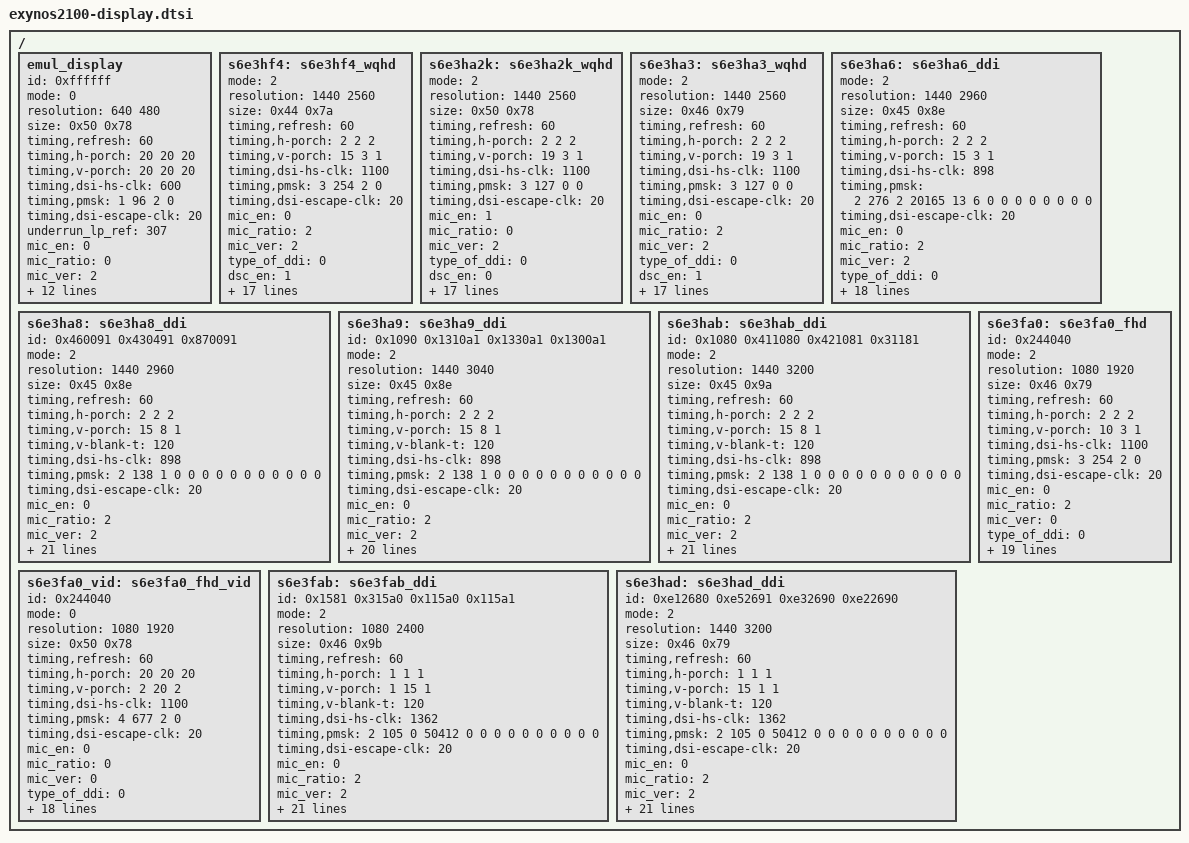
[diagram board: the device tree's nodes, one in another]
// SPDX-License-Identifier: GPL-2.0-only
/*
 * Exynos2100 LCD Panel Device Tree Source
 *
 * Copyright (C) 2026 Samsung Electronics Co., Ltd.
 *		http://www.samsung.com
 *
 */

/ {
	fragment@lcd {
		target-path = "/";
		__overlay__ {
			emul_display: emul_display {
				id = <0xffffff>;
				mode = <0>;
				resolution = <640 480>;
				size = <0x50 0x78>;
				timing,refresh = <60>;
				timing,h-porch = <20 20 20>;
				timing,v-porch = <20 20 20>;
				timing,dsi-hs-clk = <600>;
				timing,pmsk = <1 96 2 0>;
				timing,dsi-escape-clk = <20>;
				underrun_lp_ref = <307>;
				mic_en = <0>;
				mic_ratio = <0>;
				mic_ver = <2>;
				type_of_ddi = <0>;
				dsc_en = <0>;
				dsc_cnt = <0>;
				dsc_slice_num = <0>;
				data_lane = <4>;
				cmd_underrun_lp_ref = <1203>;
				vt_compensation = <10731>;
				hdr_num = <0>;
				hdr_type = <0 0 0 0>;
				hdr_max_luma = <0>;
				hdr_max_avg_luma = <0>;
				hdr_min_luma = <0>;
			};

			s6e3hf4: s6e3hf4_wqhd {
				mode = <2>;
				resolution = <1440 2560>;
				size = <0x44 0x7a>;
				timing,refresh = <60>;
				timing,h-porch = <2 2 2>;
				timing,v-porch = <15 3 1>;
				timing,dsi-hs-clk = <1100>;
				timing,pmsk = <3 254 2 0>;
				timing,dsi-escape-clk = <20>;
				mic_en = <0>;
				mic_ratio = <2>;
				mic_ver = <2>;
				type_of_ddi = <0>;
				dsc_en = <1>;
				dsc_cnt = <2>;
				dsc_slice_num = <4>;
				dsc_slice_h = <64>;
				data_lane = <4>;
				cmd_underrun_lp_ref = <5629>;
				mres_en = <0>;
				mres_number = <1>;
				mres_width = <1440 0 0>;
				mres_height = <2560 0 0>;
				mres_dsc_width = <360 0 0>;
				mres_dsc_height = <64 0 0>;
				mres_dsc_en = <1 0 0>;
				hdr_num = <1>;
				hdr_type = <2 0 0 0>;
				hdr_max_luma = <5400000>;
				hdr_max_avg_luma = <1200000>;
				hdr_min_luma = <5>;
			};

			s6e3ha2k: s6e3ha2k_wqhd {
				mode = <2>;
				resolution = <1440 2560>;
				size = <0x50 0x78>;
				timing,refresh = <60>;
				timing,h-porch = <2 2 2>;
				timing,v-porch = <19 3 1>;
				timing,dsi-hs-clk = <1100>;
				timing,pmsk = <3 127 0 0>;
				timing,dsi-escape-clk = <20>;
				mic_en = <1>;
				mic_ratio = <0>;
				mic_ver = <2>;
				type_of_ddi = <0>;
				dsc_en = <0>;
				dsc_cnt = <0>;
				dsc_slice_num = <0>;
				dsc_slice_h = <0>;
				data_lane = <4>;
				cmd_underrun_lp_ref = <1203>;
				mres_en = <0>;
				mres_number = <1>;
				mres_width = <1440 0 0>;
				mres_height = <2560 0 0>;
				mres_dsc_width = <0 0 0>;
				mres_dsc_height = <0 0 0>;
				mres_dsc_en = <0 0 0>;
				hdr_num = <1>;
				hdr_type = <2 0 0 0>;
				hdr_max_luma = <5400000>;
				hdr_max_avg_luma = <1200000>;
				hdr_min_luma = <5>;
			};

			s6e3ha3: s6e3ha3_wqhd {
				mode = <2>;
				resolution = <1440 2560>;
				size = <0x46 0x79>;
				timing,refresh = <60>;
				timing,h-porch = <2 2 2>;
				timing,v-porch = <19 3 1>;
				timing,dsi-hs-clk = <1100>;
				timing,pmsk = <3 127 0 0>;
				timing,dsi-escape-clk = <20>;
				mic_en = <0>;
				mic_ratio = <2>;
				mic_ver = <2>;
				type_of_ddi = <0>;
				dsc_en = <1>;
				dsc_cnt = <1>;
				dsc_slice_num = <1>;
				dsc_slice_h = <32>;
				data_lane = <4>;
				cmd_underrun_lp_ref = <1203>;
				mres_en = <0>;
				mres_number = <1>;
				mres_width = <1440 0 0>;
				mres_height = <2560 0 0>;
				mres_dsc_width = <1440 0 0>;
				mres_dsc_height = <32 0 0>;
				mres_dsc_en = <1 0 0>;
				hdr_num = <1>;
				hdr_type = <2 0 0 0>;
				hdr_max_luma = <5400000>;
				hdr_max_avg_luma = <1200000>;
				hdr_min_luma = <5>;
			};

			s6e3ha6: s6e3ha6_ddi {
				mode = <2>;
				resolution = <1440 2960>;
				size = <0x45 0x8e>;
				timing,refresh = <60>;
				timing,h-porch = <2 2 2>;
				timing,v-porch = <15 3 1>;
				timing,dsi-hs-clk = <898>;
				timing,pmsk = <2 276 2 20165 13 6 0 0 0 0 0 0 0 0>;
				timing,dsi-escape-clk = <20>;
				mic_en = <0>;
				mic_ratio = <2>;
				mic_ver = <2>;
				type_of_ddi = <0>;
				dsc_en = <1>;
				dsc_cnt = <2>;
				dsc_slice_num = <2>;
				dsc_slice_h = <40>;
				data_lane = <4>;
				cmd_underrun_lp_ref = <3744 5359 4367>;
				mres_en = <1>;
				mres_number = <3>;
				mres_width = <1440 1080 720>;
				mres_height = <2960 2220 1480>;
				mres_dsc_width = <720 540 360>;
				mres_dsc_height = <40 30 74>;
				mres_dsc_en = <1 1 0>;
				hdr_num = <1>;
				hdr_type = <2 0 0 0>;
				hdr_max_luma = <5400000>;
				hdr_max_avg_luma = <1200000>;
				hdr_min_luma = <5>;
			};

			s6e3ha8: s6e3ha8_ddi {
				id = <0x460091 0x430491 0x870091>;
				mode = <2>;
				resolution = <1440 2960>;
				size = <0x45 0x8e>;
				timing,refresh = <60>;
				timing,h-porch = <2 2 2>;
				timing,v-porch = <15 8 1>;
				timing,v-blank-t = <120>;
				timing,dsi-hs-clk = <898>;
				timing,pmsk = <2 138 1 0 0 0 0 0 0 0 0 0 0 0>;
				timing,dsi-escape-clk = <20>;
				mic_en = <0>;
				mic_ratio = <2>;
				mic_ver = <2>;
				type_of_ddi = <0>;
				dsc_en = <1>;
				dsc_cnt = <2>;
				dsc_slice_num = <2>;
				dsc_slice_h = <40>;
				data_lane = <4>;
				mres_en = <1>;
				mres_number = <3>;
				mres_width = <1440 1080 720>;
				mres_height = <2960 2220 1480>;
				mres_dsc_width = <720 540 360>;
				mres_dsc_height = <40 30 74>;
				mres_dsc_en = <1 1 1>;
				default_mode = <0>;
				display_mode = <
						1440 2960 60 3022 1 720 40
						1080 2220 60 5359 1 540 30
						720 1480 60 7031 1 360 74>;
				hdr_num = <1>;
				hdr_type = <2 0 0 0>;
				hdr_max_luma = <5400000>;
				hdr_max_avg_luma = <1200000>;
				hdr_min_luma = <5>;
			};

			s6e3ha9: s6e3ha9_ddi {
				id = <0x1090 0x1310a1 0x1330a1 0x1300a1>;
				mode = <2>;
				resolution = <1440 3040>;
				size = <0x45 0x8e>;
				timing,refresh = <60>;
				timing,h-porch = <2 2 2>;
				timing,v-porch = <15 8 1>;
				timing,v-blank-t = <120>;
				timing,dsi-hs-clk = <898>;
				timing,pmsk = <2 138 1 0 0 0 0 0 0 0 0 0 0 0>;
				timing,dsi-escape-clk = <20>;
				mic_en = <0>;
				mic_ratio = <2>;
				mic_ver = <2>;
				type_of_ddi = <0>;
				dsc_en = <1>;
				dsc_cnt = <2>;
				dsc_slice_num = <2>;
				dsc_slice_h = <40>;
				data_lane = <4>;
				mres_en = <0>;
				mres_number = <3>;
				mres_width = <1440 1080 720>;
				mres_height = <3040 2280 1520>;
				mres_dsc_width = <720 540 360>;
				mres_dsc_height = <40 30 74>;
				mres_dsc_en = <1 1 1>;
				default_mode = <0>;
				display_mode = <1440 3040 60 2877 1 720 40>;
				hdr_num = <1>;
				hdr_type = <2 0 0 0>;
				hdr_max_luma = <5400000>;
				hdr_max_avg_luma = <1200000>;
				hdr_min_luma = <5>;
			};

			s6e3hab: s6e3hab_ddi {
				id = <0x1080 0x411080 0x421081 0x31181>;
				mode = <2>;
				resolution = <1440 3200>;
				size = <0x45 0x9a>;
				timing,refresh = <60>;
				timing,h-porch = <2 2 2>;
				timing,v-porch = <15 8 1>;
				timing,v-blank-t = <120>;
				timing,dsi-hs-clk = <898>;
				timing,pmsk = <2 138 1 0 0 0 0 0 0 0 0 0 0 0>;
				timing,dsi-escape-clk = <20>;
				mic_en = <0>;
				mic_ratio = <2>;
				mic_ver = <2>;
				type_of_ddi = <0>;
				dsc_en = <1>;
				dsc_cnt = <2>;
				dsc_slice_num = <2>;
				dsc_slice_h = <40>;
				data_lane = <4>;
				mres_en = <1>;
				mres_number = <3>;
				mres_width = <1440 1080 720>;
				mres_height = <3200 2400 1600>;
				mres_dsc_width = <720 540 360>;
				mres_dsc_height = <40 40 80>;
				mres_dsc_en = <1 1 1>;
				default_mode = <0>;
				display_mode = <
						1440 3200 60 3022 1 720 40
						1080 2400 60 5115 1 540 40
						1080 2400 120 660 1 540 40
						720 1600 60 6922 1 360 80
						720 1600 120 2467 1 360 80 >;
				hdr_num = <1>;
				hdr_type = <2 0 0 0>;
				hdr_max_luma = <5400000>;
				hdr_max_avg_luma = <1200000>;
				hdr_min_luma = <5>;
			};

			s6e3fa0: s6e3fa0_fhd {
				id = <0x244040>;
				mode = <2>;
				resolution = <1080 1920>;
				size = <0x46 0x79>;
				timing,refresh = <60>;
				timing,h-porch = <2 2 2>;
				timing,v-porch = <10 3 1>;
				timing,dsi-hs-clk = <1100>;
				timing,pmsk = <3 254 2 0>;
				timing,dsi-escape-clk = <20>;
				mic_en = <0>;
				mic_ratio = <2>;
				mic_ver = <0>;
				type_of_ddi = <0>;
				dsc_en = <0>;
				dsc_cnt = <0>;
				dsc_slice_num = <0>;
				dsc_slice_h = <40>;
				data_lane = <4>;
				mres_en = <0>;
				mres_number = <1>;
				mres_width = <1080 0 0>;
				mres_height = <1920 0 0>;
				mres_dsc_width = <0 0 0>;
				mres_dsc_height = <0 0 0>;
				mres_dsc_en = <0 0 0>;
				default_mode = <0>;
				display_mode = <1080 1920 60 2467 0 0 0>;
				hdr_num = <1>;
				hdr_type = <2 0 0 0>;
				hdr_max_luma = <5400000>;
				hdr_max_avg_luma = <1200000>;
				hdr_min_luma = <5>;
			};

			s6e3fa0_vid: s6e3fa0_fhd_vid {
				id = <0x244040>;
				mode = <0>;
				resolution = <1080 1920>;
				size = <0x50 0x78>;
				timing,refresh = <60>;
				timing,h-porch = <20 20 20>;
				timing,v-porch = <2 20 2>;
				timing,dsi-hs-clk = <1100>;
				timing,pmsk = <4 677 2 0>;
				timing,dsi-escape-clk = <20>;
				mic_en = <0>;
				mic_ratio = <0>;
				mic_ver = <0>;
				type_of_ddi = <0>;
				dsc_en = <0>;
				dsc_cnt = <0>;
				dsc_slice_num = <0>;
				data_lane = <4>;
				cmd_underrun_cnt = <4942>;
				vt_compensation = <39>;
				mres_en = <0>;
				mres_number = <3>;
				mres_width = <1440 1080 720>;
				mres_height = <2960 2220 1480>;
				mres_dsc_width = <720 540 360>;
				mres_dsc_height = <40 30 74>;
				mres_dsc_en = <1 1 0>;
				hdr_num = <1>;
				hdr_type = <2 0 0 0>;
				hdr_max_luma = <5400000>;
				hdr_max_avg_luma = <1200000>;
				hdr_min_luma = <5>;
			};

			s6e3fab: s6e3fab_ddi {
				id = <0x1581 0x315a0 0x115a0 0x115a1>;
				mode = <2>;
				resolution = <1080 2400>;
				size = <0x46 0x9b>;
				timing,refresh = <60>;
				timing,h-porch = <1 1 1>;
				timing,v-porch = <1 15 1>;
				timing,v-blank-t = <120>;
				timing,dsi-hs-clk = <1362>;
				timing,pmsk = <2 105 0 50412 0 0 0 0 0 0 0 0 0 0>;
				timing,dsi-escape-clk = <20>;
				mic_en = <0>;
				mic_ratio = <2>;
				mic_ver = <2>;
				type_of_ddi = <0>;
				dsc_en = <1>;
				dsc_cnt = <2>;
				dsc_slice_num = <2>;
				dsc_slice_h = <120>;
				data_lane = <4>;
				mres_en = <1>;
				mres_number = <3>;
				mres_width = <1440 1080 720>;
				mres_height = <3200 2400 1600>;
				mres_dsc_width = <720 540 360>;
				mres_dsc_height = <40 40 80>;
				mres_dsc_en = <1 1 1>;
				default_mode = <0>;
				display_mode = <
						1080 2400 60 10361 1 540 120
						1080 2400 120 3337 1 540 120 >;
				hdr_num = <1>;
				hdr_type = <2 0 0 0>;
				hdr_max_luma = <5400000>;
				hdr_max_avg_luma = <1200000>;
				hdr_min_luma = <5>;
			};

			s6e3had: s6e3had_ddi {
				id = <0xe12680 0xe52691 0xe32690 0xe22690>;
				mode = <2>;
				resolution = <1440 3200>;
				size = <0x46 0x79>;
				timing,refresh = <60>;
				timing,h-porch = <1 1 1>;
				timing,v-porch = <15 1 1>;
				timing,v-blank-t = <120>;
				timing,dsi-hs-clk = <1362>;
				timing,pmsk = <2 105 0 50412 0 0 0 0 0 0 0 0 0 0>;
				timing,dsi-escape-clk = <20>;
				mic_en = <0>;
				mic_ratio = <2>;
				mic_ver = <2>;
				type_of_ddi = <0>;
				dsc_en = <1>;
				dsc_cnt = <2>;
				dsc_slice_num = <2>;
				dsc_slice_h = <40>;
				data_lane = <4>;
				mres_en = <1>;
				mres_number = <3>;
				mres_width = <1440 1080 720>;
				mres_height = <3200 2400 1600>;
				mres_dsc_width = <720 540 360>;
				mres_dsc_height = <40 40 80>;
				mres_dsc_en = <1 1 1>;
				default_mode = <0>;
				display_mode = <
						1440 3200 60 7834 1 720 40
						1440 3200 120 810 1 720 40
						1080 2400 60 10361 1 540 40
						1080 2400 120 3337 1 540 40
						720 1600 60 12168 1 360 80
						720 1600 120 5144 1 360 80 >;
				hdr_num = <1>;
				hdr_type = <2 0 0 0>;
				hdr_max_luma = <5400000>;
				hdr_max_avg_luma = <1200000>;
				hdr_min_luma = <5>;
			};
		};
	};
};
